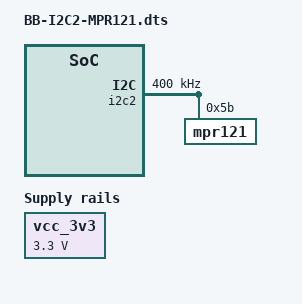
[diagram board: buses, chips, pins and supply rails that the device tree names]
/*
 * Copyright (C) 2020 Seeed Studio
 * Baozhu Zuo <zuobaozhu@gmail.com>
 *
 * MIT License
 *
 */

/dts-v1/;
/plugin/;

#include <dt-bindings/input/input.h>

/ {
        compatible = "ti,beaglebone", "ti,beaglebone-black", "ti,beaglebone-green";

	/* identification */
	part-number = "BB-I2C2-MPR121";
	version = "00A0";      

	fragment@0 {
		target-path="/";
		__overlay__ {
			chosen {
				overlays {
					BB-I2C2-MPR121 = __TIMESTAMP__;
				};
			};

			aliases {
				/* SLOT I2C1 */
				/*
				mpr121 = "/ocp/i2c@4802a000/mpr121@5b";
				*/
				/* SLOT I2C2 */
				mpr121 = "/ocp/i2c@4819c000/mpr121@5b";
			};
			
		        vcc_3v3: regulator-vcc-3v3 {
        	        	compatible = "regulator-fixed";
                		regulator-name = "VCC-3V3";
                		regulator-min-microvolt = <3300000>;
                		regulator-max-microvolt = <3300000>;
		        };

		};
	};

	fragment@1 {
		/* SLOT I2C1 */
		/*
		target = <&i2c1>;
		*/
		/* SLOT I2C2 */
		target = <&i2c2>;

		__overlay__ {
			status = "okay";

			clock-frequency = <400000>;

			#address-cells = <1>;
			#size-cells = <0>;

			mpr121@5b {
				compatible = "mpr121";
				reg = <0x5b>;

#if 0 //use the touchkey
				compatible = "fsl,mpr121-touchkey";
				reg = <0x5b>;
				autorepeat;
				vdd-supply = <&vcc_3v3>;
				linux,keycodes = <KEY_0>, <KEY_1>, <KEY_2>, <KEY_3>,<KEY_4>, <KEY_5>, <KEY_6>, <KEY_7>,<KEY_8>, <KEY_9>, <KEY_A>, <KEY_B>;
#endif
		    	};
        	};
	};
};

